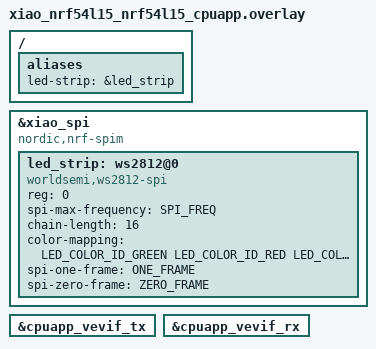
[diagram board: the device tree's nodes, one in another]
/*
 * Copyright (c) 2024 Nordic Semiconductor ASA
 *
 * SPDX-License-Identifier: Apache-2.0
 */

//#include <zephyr/dt-bindings/gpio/gpio.h>
#include <zephyr/dt-bindings/led/led.h>
#include "../nrf54l15-bindings.h"

&xiao_spi {
	compatible = "nordic,nrf-spim";
	led_strip: ws2812@0 {
		compatible = "worldsemi,ws2812-spi";
		/* WS2812 LED strip configuration */
		reg = <0>;                  /* P2.08 (D6/TX on XIAO nRF54L15) - FLPR can only use Port 2! */
		spi-max-frequency = <SPI_FREQ>;

		/* WS2812 */
		chain-length = <16>; /* arbitrary; change at will */
		color-mapping = <LED_COLOR_ID_GREEN
				 LED_COLOR_ID_RED
				 LED_COLOR_ID_BLUE>;
		spi-one-frame = <ONE_FRAME>;
		spi-zero-frame = <ZERO_FRAME>;
	};

	
};

/ {
	aliases { 
		led-strip = &led_strip;
	};
};

/* Enable GPIO port 2 for WS2812 data pin (FLPR requirement) */
//&gpio2 {
//	status = "okay";
//};

/* Enable MBOX communication with FLPR core */
&cpuapp_vevif_tx {
	status = "okay";
};

&cpuapp_vevif_rx {
	status = "okay";
};
